AUTOSAR XML (schema 4-3-0)
package /ComponentTypes
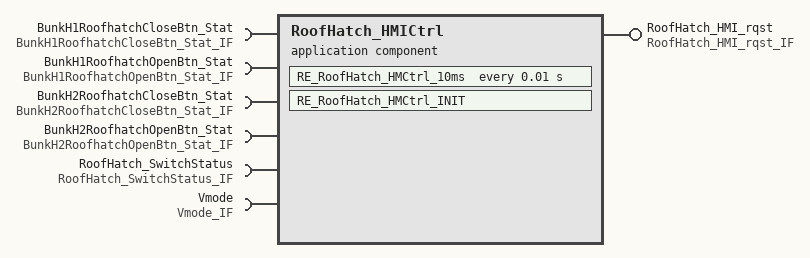
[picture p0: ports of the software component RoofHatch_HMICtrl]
  application sw component type RoofHatch_HMICtrl
    provide port RoofHatch_HMI_rqst: nonqueued-sender-com-spec=RoofHatch_HMI_rqst, provided-interface=RoofHatch_HMI_rqst_IF
    6 x require port:
      BunkH1RoofhatchCloseBtn_Stat: nonqueued-receiver-com-spec{data-element=PushButtonStatus, filter=data-filter-type=ALWAYS}, required-interface=BunkH1RoofhatchCloseBtn_Stat_IF
      BunkH1RoofhatchOpenBtn_Stat: nonqueued-receiver-com-spec{data-element=PushButtonStatus, filter=data-filter-type=ALWAYS}, required-interface=BunkH1RoofhatchOpenBtn_Stat_IF
      BunkH2RoofhatchCloseBtn_Stat: nonqueued-receiver-com-spec{data-element=PushButtonStatus, filter=data-filter-type=ALWAYS}, required-interface=BunkH2RoofhatchCloseBtn_Stat_IF
      BunkH2RoofhatchOpenBtn_Stat: nonqueued-receiver-com-spec{data-element=PushButtonStatus, filter=data-filter-type=ALWAYS}, required-interface=BunkH2RoofhatchOpenBtn_Stat_IF
      RoofHatch_SwitchStatus: nonqueued-receiver-com-spec{data-element=A3PosSwitchStatus, filter=data-filter-type=ALWAYS}, required-interface=RoofHatch_SwitchStatus_IF
      Vmode: nonqueued-receiver-com-spec{data-element=Vmode, filter=data-filter-type=ALWAYS}, required-interface=Vmode_IF
    behavior RoofHatch_HMICtrl_InternalBehavior
      timing event TMT_RE_RoofHatch_HMCtrl_10ms: start-on-event=RE_RoofHatch_HMCtrl_10ms, period=0.01
      init event RE_RoofHatch_HMCtrl_INIT_InitEvent: start-on-event=RE_RoofHatch_HMCtrl_INIT
      runnable RE_RoofHatch_HMCtrl_10ms
        data-receive-point-by-arguments:
          6 x access:
            REC_BunkH1RoofhatchCloseBtn_Stat_PushButtonStatus: accessed-variable=BunkH1RoofhatchCloseBtn_Stat.PushButtonStatus
            REC_BunkH1RoofhatchOpenBtn_Stat_PushButtonStatus: accessed-variable=BunkH1RoofhatchOpenBtn_Stat.PushButtonStatus
            REC_BunkH2RoofhatchCloseBtn_Stat_PushButtonStatus: accessed-variable=BunkH2RoofhatchCloseBtn_Stat.PushButtonStatus
            REC_BunkH2RoofhatchOpenBtn_Stat_PushButtonStatus: accessed-variable=BunkH2RoofhatchOpenBtn_Stat.PushButtonStatus
            REC_RoofHatch_SwitchStatus_A3PosSwitchStatus: accessed-variable=RoofHatch_SwitchStatus.A3PosSwitchStatus
            REC_Vmode_Vmode: accessed-variable=Vmode.Vmode
        data-send-points:
          access SEND_RoofHatch_HMI_rqst_RoofHatch_HMI_rqst: accessed-variable=RoofHatch_HMI_rqst.RoofHatch_HMI_rqst
      runnable RE_RoofHatch_HMCtrl_INIT
  swc implementation RoofHatch_HMICtrl_Implementation: behavior=RoofHatch_HMICtrl_InternalBehavior
